# SGX register map
Vendor: Texas Instruments
Peripheral module from a debugger description file (folder omap36xx).
Registers are 32-bit, access per field, reset 0x0 unless marked. A register's access mark holds for its fields unless they carry their own. Offsets are as the file gives them; lines under a group give offsets from that group; [hi:lo] are bit positions; {n}, {i} and the like mark numbered series; 'fields as' and 'values as' point back to an identical list; <NAME> marks a mode.

## SGX
0xFE00 OCP_REVISION ro reset not defined
  [31:0] REVISIONID — Revision value.
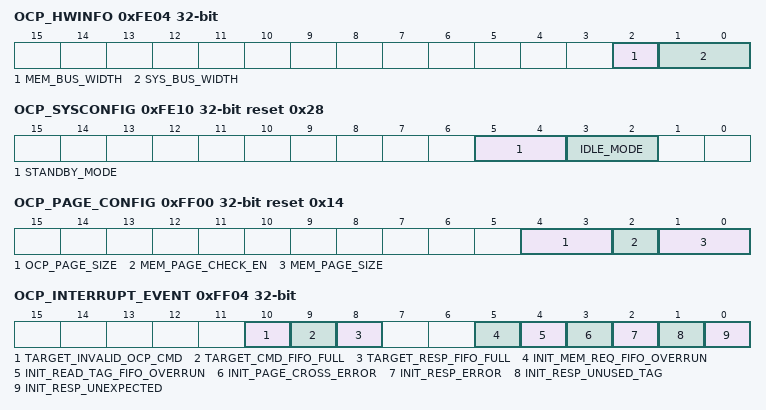
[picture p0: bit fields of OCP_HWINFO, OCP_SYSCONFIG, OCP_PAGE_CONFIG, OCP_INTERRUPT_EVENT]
0xFE04 OCP_HWINFO ro (reset mask 0xFFFFFFF8) — Hardware implementation information
  [2] MEM_BUS_WIDTH — Memory bus width:
    0=MEM_BUS_WIDTH_0_r (Memory bus width is 64 bits); 1=MEM_BUS_WIDTH_1_r (Memory bus width is 128 bits)
  [1:0] SYS_BUS_WIDTH — System bus width:
    0=SYS_BUS_WIDTH_0_r (System bus width is 32 bits); 1=SYS_BUS_WIDTH_1_r (System bus width is 64 bits); 2=SYS_BUS_WIDTH_2_r (System bus width is 128 bits); 3=SYS_BUS_WIDTH_3_r (Reserved)
0xFE10 OCP_SYSCONFIG reset 0x28 — System Configuration register
  [5:4] STANDBY_MODE rw — Clock standby mode:0x2, 0x3: Smart Standby mode .
    0=Force Standby mode; 1=No Standby mode
  [3:2] IDLE_MODE rw — Clock Idle mode:0x2, 0x3: Smart Idle mode .
    0=Force Idle mode; 1=No idle mode
0xFE24 OCP_IRQSTATUS_RAW_0 — Raw IRQ 0 Status
  [0] INIT_MINTERRUPT_RAW rw — Interrupt 0 - master port raw event:
    0=INIT_MINTERRUPT_RAW_0_w (no action.); 0=INIT_MINTERRUPT_RAW_0_r (no event pending.); 1=INIT_MINTERRUPT_RAW_1_r (event pending.); 1=INIT_MINTERRUPT_RAW_1_w (set event (used for debug).)
0xFE28 OCP_IRQSTATUS_RAW_1 — Raw IRQ 1 Status . Slave port interrupt.
  [0] TARGET_SINTERRUPT_RAW rw — Interrupt 1- slave port raw event
    0=TARGET_SINTERRUPT_RAW_0_w (no action.); 0=TARGET_SINTERRUPT_RAW_0_r (no event pending.); 1=TARGET_SINTERRUPT_RAW_1_r (event pending.); 1=TARGET_SINTERRUPT_RAW_1_w (set event (used for debug).)
0xFE2C OCP_IRQSTATUS_RAW_2 — Raw IRQ 2 Status. Thalia interrupt.
  [0] THALIA_IRQ_RAW rw — Interrupt 2 - Thalia raw event
    0=THALIA_IRQ_RAW_0_w (no action.); 0=THALIA_IRQ_RAW_0_r (no event pending.); 1=THALIA_IRQ_RAW_1_r (event pending.); 1=THALIA_IRQ_RAW_1_w (set event (used for debug).)
0xFE30 OCP_IRQSTATUS_0 — Interrupt 0 Status event. Master port interrupt.
  [0] INIT_MINTERRUPT_STATUS rw — Interrupt 0 - Master port status event
    0=INIT_MINTERRUPT_STATUS_0_w (no action.); 0=INIT_MINTERRUPT_STATUS_0_r (no event pending.); 1=INIT_MINTERRUPT_STATUS_1_r (event pending and interrupt enabled.); 1=INIT_MINTERRUPT_STATUS_1_w (clear event.)
0xFE34 OCP_IRQSTATUS_1 — Interrupt 1 - slave port status event
  [0] TARGET_SINTERRUPT_STATUS rw
    0=TARGET_SINTERRUPT_STATUS_0_w (no action.); 0=TARGET_SINTERRUPT_STATUS_0_r (no event pending.); 1=TARGET_SINTERRUPT_STATUS_1_r (event pending and interrupt enabled.); 1=TARGET_SINTERRUPT_STATUS_1_w (clear event.)
0xFE38 OCP_IRQSTATUS_2 — Interrupt 2 - Thalia status event
  [0] THALIA_IRQ_STATUS rw — Interrupt 2 - Thalia (core) status event
    0=THALIA_IRQ_STATUS_0_w (no action.); 0=THALIA_IRQ_STATUS_0_r (no event pending.); 1=THALIA_IRQ_STATUS_1_r (event pending and interrupt enabled.); 1=THALIA_IRQ_STATUS_1_w (clear event.)
0xFE3C OCP_IRQENABLE_SET_0 — Enable Interrupt 0 - Master port
  [0] INIT_MINTERRUPT_ENABLE rw — Enable interrupt 0 - master port
    0=INIT_MINTERRUPT_ENABLE_0_w (no action.); 0=INIT_MINTERRUPT_ENABLE_0_r (interrupt is enabled.); 1=INIT_MINTERRUPT_ENABLE_1_r (interrupt is disabled.); 1=INIT_MINTERRUPT_ENABLE_1_w (enable interrupt.)
0xFE40 OCP_IRQENABLE_SET_1 — Enable Interrupt 1. Target port interrupt.
  [0] TARGET_SINTERRUPT_ENABLE rw — Enable interrupt 1 - slave port interrupt
    0=TARGET_SINTERRUPT_ENABLE_0_w (no action.); 0=TARGET_SINTERRUPT_ENABLE_0_r (interrupt is enabled.); 1=TARGET_SINTERRUPT_ENABLE_1_r (interrupt is disabled.); 1=TARGET_SINTERRUPT_ENABLE_1_w (enable interrupt.)
0xFE44 OCP_IRQENABLE_SET_2 — Enable Interrupt 2. Thalia (core) interrupt.
  [0] THALIA_IRQ_ENABLE rw — Enable interrupt 2 - Thalia (core) interrupt
    0=THALIA_IRQ_ENABLE_0_w (no action.); 0=THALIA_IRQ_ENABLE_0_r (interrupt is enabled.); 1=THALIA_IRQ_ENABLE_1_r (interrupt is disabled.); 1=THALIA_IRQ_ENABLE_1_w (enable interrupt.)
0xFE48 OCP_IRQENABLE_CLR_0 — Disable Interrupt 0 - Master port
  [0] INIT_MINTERRUPT_DISABLE rw — Disable interrupt 0 - master port
    0=INIT_MINTERRUPT_DISABLE_0_w (no action.); 0=INIT_MINTERRUPT_DISABLE_0_r (interrupt is enabled.); 1=INIT_MINTERRUPT_DISABLE_1_r (interrupt is disabled.); 1=INIT_MINTERRUPT_DISABLE_1_w (disable interrupt.)
0xFE4C OCP_IRQENABLE_CLR_1 — Disable Interrupt 1 - slave port
  [0] TARGET_SINTERRUPT_DISABLE rw — Disable interrupt 1 - slave port
    0=TARGET_SINTERRUPT_DISABLE_0_w (no action.); 0=TARGET_SINTERRUPT_DISABLE_0_r (interrupt is enabled.); 1=TARGET_SINTERRUPT_DISABLE_1_r (interrupt is disabled.); 1=TARGET_SINTERRUPT_DISABLE_1_w (disable interrupt.)
0xFE50 OCP_IRQENABLE_CLR_2 — Disable Interrupt 2 -Thalia (core) interrupt
  [0] THALIA_IRQ_DISABLE rw — Disable interrupt 2 - Thalia (core) interrupt
    0=THALIA_IRQ_DISABLE_0_w (no action.); 0=THALIA_IRQ_DISABLE_0_r (interrupt is enabled.); 1=THALIA_IRQ_DISABLE_1_r (interrupt is disabled.); 1=THALIA_IRQ_DISABLE_1_w (disable interrupt.)
0xFF00 OCP_PAGE_CONFIG reset 0x14 — Configure memory pages..
  [4:3] OCP_PAGE_SIZE rw — Defines the page size on OCP memory interface
    0=Page size is 4 KB; 1=Page size is 2KB; 2=Page size is 1KB; 3=Page size is 512B
  [2] MEM_PAGE_CHECK_EN rw — Enable page boundary checking.
    0=Page boundary checking disabled; 1=Page boundary checking enabled
  [1:0] MEM_PAGE_SIZE rw — Defines the page size on internal memory interface
    values as OCP_PAGE_SIZE
0xFF04 OCP_INTERRUPT_EVENT — Interrupt events
  [10] TARGET_INVALID_OCP_CMD rw — Invalid command from OCP
    0=TARGET_INVALID_OCP_CMD_0_w (clear the event.); 0=TARGET_INVALID_OCP_CMD_0_r (no event pending.); 1=TARGET_INVALID_OCP_CMD_1_r (event pending.); 1=TARGET_INVALID_OCP_CMD_1_w (set event and interrupt if enabled (debug only).)
  [9] TARGET_CMD_FIFO_FULL rw — Command FIFO full
    0=TARGET_CMD_FIFO_FULL_0_w (Write 0 to clear the event.); 0=TARGET_CMD_FIFO_FULL_0_r (Read 0 implies no event pending.); 1=TARGET_CMD_FIFO_FULL_1_r (Read 1 indicates event pending.); 1=TARGET_CMD_FIFO_FULL_1_w (Write 1 to set event and interrupt if enabled (debug only).)
  [8] TARGET_RESP_FIFO_FULL rw — Response FIFO full
    0=TARGET_RESP_FIFO_FULL_0_w (clear the event.); 0=TARGET_RESP_FIFO_FULL_0_r (no event pending.); 1=TARGET_RESP_FIFO_FULL_1_r (event pending.); 1=TARGET_RESP_FIFO_FULL_1_w (set event and interrupt if enabled (debug only).)
  [5] INIT_MEM_REQ_FIFO_OVERRUN rw — Memory request FIFO overrun.
    0=INIT_MEM_REQ_FIFO_OVERRUN_0_w (clear the event.); 0=INIT_MEM_REQ_FIFO_OVERRUN_0_r (no event pending.); 1=INIT_MEM_REQ_FIFO_OVERRUN_1_r (event pending.); 1=INIT_MEM_REQ_FIFO_OVERRUN_1_w (set event and interrupt if enabled (debug only).)
  [4] INIT_READ_TAG_FIFO_OVERRUN rw — Read tag FIFO overrun.
    0=INIT_READ_TAG_FIFO_OVERRUN_0_w (clear the event.); 0=INIT_READ_TAG_FIFO_OVERRUN_0_r (no event pending.); 1=INIT_READ_TAG_FIFO_OVERRUN_1_r (event pending.); 1=INIT_READ_TAG_FIFO_OVERRUN_1_w (set event and interrupt if enabled (debug only).)
  [3] INIT_PAGE_CROSS_ERROR rw — Memory page had been crossed during a burst.
    0=INIT_PAGE_CROSS_ERROR_0_w (clear the event.); 0=INIT_PAGE_CROSS_ERROR_0_r (no event pending.); 1=INIT_PAGE_CROSS_ERROR_1_r (event pending.); 1=INIT_PAGE_CROSS_ERROR_1_w (set event and interrupt if enabled (debug only).)
  [2] INIT_RESP_ERROR rw — Receiving error response.
    0=INIT_RESP_ERROR_0_w (clear the event.); 0=INIT_RESP_ERROR_0_r (no event pending.); 1=INIT_RESP_ERROR_1_r (event pending.); 1=INIT_RESP_ERROR_1_w (set event and interrupt if enabled (debug only).)
  [1] INIT_RESP_UNUSED_TAG rw — Receiving response on an unused tag.
    0=INIT_RESP_UNUSED_TAG_0_w (clear the event.); 0=INIT_RESP_UNUSED_TAG_0_r (no event pending.); 1=INIT_RESP_UNUSED_TAG_1_r (event pending.); 1=INIT_RESP_UNUSED_TAG_1_w (set event and interrupt if enabled (debug only).)
  [0] INIT_RESP_UNEXPECTED rw — Receiving response when not expected
    0=INIT_RESP_UNEXPECTED_0_w (clear the event.); 0=INIT_RESP_UNEXPECTED_0_r (no event pending.); 1=INIT_RESP_UNEXPECTED_1_r (event pending.); 1=INIT_RESP_UNEXPECTED_1_w (set event and interrupt if enabled (debug only).)
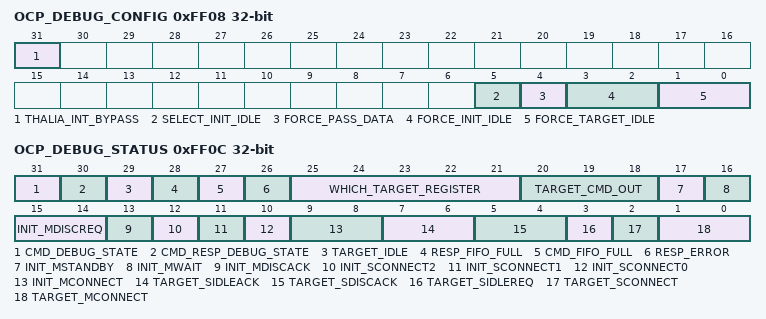
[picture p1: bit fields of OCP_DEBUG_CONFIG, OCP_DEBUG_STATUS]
0xFF08 OCP_DEBUG_CONFIG — Configuration of debug modes.
  [31] THALIA_INT_BYPASS rw — Bypass OCP IPG interrupt logic.
    0=Don't Bypass; 1=Bypass core interrupt to IO pin, ie disregard the interrupt enable setting in IPG register
  [5] SELECT_INIT_IDLE rw — To select which idle the disconnect protocol should act on 0
    0=Whole SGX Idle; 1=OCP initiator idle only
  [4] FORCE_PASS_DATA rw — Forces the initiator to pass data independent of disconnect protocol
    0=Normal mode. Don't force.; 1=Never fence request to OCP
  [3:2] FORCE_INIT_IDLE rw — Forces the OCP master port to Idle.
    0=Normal mode - no force; 1=Force port to be always Idle; 2=Forces target port to never be in Idle mode; 3=Normal mode. No force.
  [1:0] FORCE_TARGET_IDLE rw — Forces the OCP target port to Idle.
    values as FORCE_INIT_IDLE
0xFF0C OCP_DEBUG_STATUS reset not defined — Status of debug.
  [31] CMD_DEBUG_STATE rw — Target command state machine
    0=Idle; 1=Accept command
  [30] CMD_RESP_DEBUG_STATE rw — Target response state machine
    0=Send accept; 1=Wait accept
  [29] TARGET_IDLE ro
  [28] RESP_FIFO_FULL ro — Target response FIFO full
  [27] CMD_FIFO_FULL ro — Target command FIFO full
  [26] RESP_ERROR ro — Respond to OCP with error, which could be caused by either address misalignment or invalid byte enable.
  [25:21] WHICH_TARGET_REGISTER rw — Indicates which OCP target registers to read
  [20:18] TARGET_CMD_OUT ro — Command received from OCP
    0=TARGET_CMD_OUT_0_r (Command WRSYS received); 1=TARGET_CMD_OUT_1_r (Command RDSYS received); 2=TARGET_CMD_OUT_2_r (Command WR_ERROR received); 3=TARGET_CMD_OUT_3_r (Command RD_ERROR received); 4=TARGET_CMD_OUT_4_r (Command CHK_WRADDR_PAGE received. Not used.); 5=TARGET_CMD_OUT_5_r (Command CHK_RDADDR_PAGE received. Not used.); 6=TARGET_CMD_OUT_6_r (Command TARGET_REG_WRITE received.); 7=TARGET_CMD_OUT_7_r (Command TARGET_REG_READ received)
  [17] INIT_MSTANDBY ro — Status of init_MStandby signal
  [16] INIT_MWAIT ro — Status of init_MWait signal
  [15:14] INIT_MDISCREQ ro — Disconnect status of the OCP interface
    0=INIT_MDISCREQ_0_r (State is FUNCT); 1=INIT_MDISCREQ_1_r (State is SLEEP TRANS); 2=INIT_MDISCREQ_2_r (Reserved); 3=INIT_MDISCREQ_3_r (State is IDLE.)
  [13] INIT_MDISCACK rw — Memory request FIFO full
    0=INIT_MDISCACK_0_w (clear the event.); 0=INIT_MDISCACK_0_r (no event pending); 1=INIT_MDISCACK_1_r (event pending); 1=INIT_MDISCACK_1_w (set the event and interrupt if enabled (debug only))
  [12] INIT_SCONNECT2 ro — Defines whether to wait in M_WAIT state for MConnect FSM
    0=INIT_SCONNECT2_0_r (Skip M_WAIT state.); 1=INIT_SCONNECT2_1_r (Wait in M_WAIT state.)
  [11] INIT_SCONNECT1 ro — Defines the busy-ness state of the slave
    0=INIT_SCONNECT1_0_r (Slave is drained); 1=INIT_SCONNECT1_1_r (Slave is loaded)
  [10] INIT_SCONNECT0 ro — Disconnect from slave
    0=INIT_SCONNECT0_0_r (Disconnect request from slave.); 1=INIT_SCONNECT0_1_r (Connect request from slave.)
  [9:8] INIT_MCONNECT ro — Initiator MConnect state
    0=INIT_MCONNECT_0_r (State is M_OFF.); 1=INIT_MCONNECT_1_r (State is M_WAIT.); 2=INIT_MCONNECT_2_r (State is M_DISC.); 3=INIT_MCONNECT_3_r (State is M_CON)
  [7:6] TARGET_SIDLEACK ro — Acknowledge the SIdleAck state machine
    0=TARGET_SIDLEACK_0_r (State is FUNCT); 1=TARGET_SIDLEACK_1_r (State is SLEEP TRANS); 2=TARGET_SIDLEACK_2_r (Reserved); 3=TARGET_SIDLEACK_3_r (State is IDLE.)
  [5:4] TARGET_SDISCACK ro — Acknowledge the SDiscAck state machine
    0=TARGET_SDISCACK_0_r (State is FUNCT); 1=TARGET_SDISCACK_1_r (State is TRANS); 2=TARGET_SDISCACK_2_r (Reserved); 3=TARGET_SDISCACK_3_r (State is IDLE.)
  [3] TARGET_SIDLEREQ ro — Request the target to go idle.
    0=TARGET_SIDLEREQ_0_r (Don't go idle, or go active.); 1=TARGET_SIDLEREQ_1_r (Go idle.)
  [2] TARGET_SCONNECT ro — Target SConnect state
    0=TARGET_SCONNECT_0_r (Disconnect interface.); 1=TARGET_SCONNECT_1_r (Connect OCP interface.)
  [1:0] TARGET_MCONNECT ro — Target MConnect state
    0=TARGET_MCONNECT_0_r (Target is in M_OFF state); 1=TARGET_MCONNECT_1_r (Target is in M_WAIT disconnect state.); 2=TARGET_MCONNECT_2_r (Target is in M_DISC state.); 3=TARGET_MCONNECT_3_r (Target is in M_CON state.)
